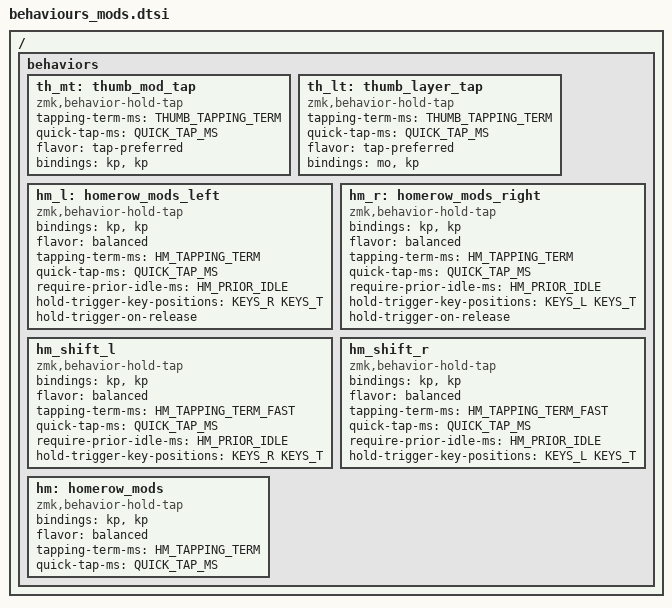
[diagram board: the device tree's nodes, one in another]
// Make sure settings.dtsi is included before this file

#define HM_TAPPING_TERM 300
#define HM_TAPPING_TERM_FAST 200
#define HM_PRIOR_IDLE 150

#define THUMB_TAPPING_TERM 300

#define QUICK_TAP_MS 175


/ {

    behaviors {
        th_mt: thumb_mod_tap {
            compatible = "zmk,behavior-hold-tap";
            #binding-cells = <2>;
            tapping-term-ms = <THUMB_TAPPING_TERM>;
            quick-tap-ms = <QUICK_TAP_MS>;
            flavor = "tap-preferred";
            bindings = <&kp>, <&kp>;
        };

        th_lt: thumb_layer_tap {
            compatible = "zmk,behavior-hold-tap";
            #binding-cells = <2>;
            tapping-term-ms = <THUMB_TAPPING_TERM>;
            quick-tap-ms = <QUICK_TAP_MS>;
            flavor = "tap-preferred";
            bindings = <&mo>, <&kp>;
        };

        hm_l: homerow_mods_left {
            compatible = "zmk,behavior-hold-tap";
            #binding-cells = <2>;
            bindings = <&kp>,  <&kp>;

            flavor = "balanced";
            tapping-term-ms = <HM_TAPPING_TERM>;
            quick-tap-ms = <QUICK_TAP_MS>;
            require-prior-idle-ms = <HM_PRIOR_IDLE>;

            hold-trigger-key-positions = <KEYS_R KEYS_T>;
            hold-trigger-on-release;
        };

        hm_r: homerow_mods_right {
            compatible = "zmk,behavior-hold-tap";
            #binding-cells = <2>;
            bindings = <&kp>, <&kp>;

            flavor = "balanced";
            tapping-term-ms = <HM_TAPPING_TERM>;
            quick-tap-ms = <QUICK_TAP_MS>;
            require-prior-idle-ms = <HM_PRIOR_IDLE>;

            hold-trigger-key-positions = <KEYS_L KEYS_T>;
            hold-trigger-on-release;
        };


        hm_shift_l: hm_shift_l {
            compatible = "zmk,behavior-hold-tap";
            #binding-cells = <2>;
            bindings = <&kp>, <&kp>;

            flavor = "balanced";
            tapping-term-ms = <HM_TAPPING_TERM_FAST>;
            quick-tap-ms = <QUICK_TAP_MS>;
            require-prior-idle-ms = <HM_PRIOR_IDLE>;

            hold-trigger-key-positions = <KEYS_R KEYS_T>;
        };

        hm_shift_r: hm_shift_r {
            compatible = "zmk,behavior-hold-tap";
            #binding-cells = <2>;
            bindings = <&kp>, <&kp>;

            flavor = "balanced";
            tapping-term-ms = <HM_TAPPING_TERM_FAST>;
            quick-tap-ms = <QUICK_TAP_MS>;
            require-prior-idle-ms = <HM_PRIOR_IDLE>;

            hold-trigger-key-positions = <KEYS_L KEYS_T>;
        };

        hm: homerow_mods {
            compatible = "zmk,behavior-hold-tap";
            #binding-cells = <2>;
            bindings = <&kp>, <&kp>;

            flavor = "balanced";
            tapping-term-ms = <HM_TAPPING_TERM>;
            quick-tap-ms = <QUICK_TAP_MS>;
        };
    };
};
